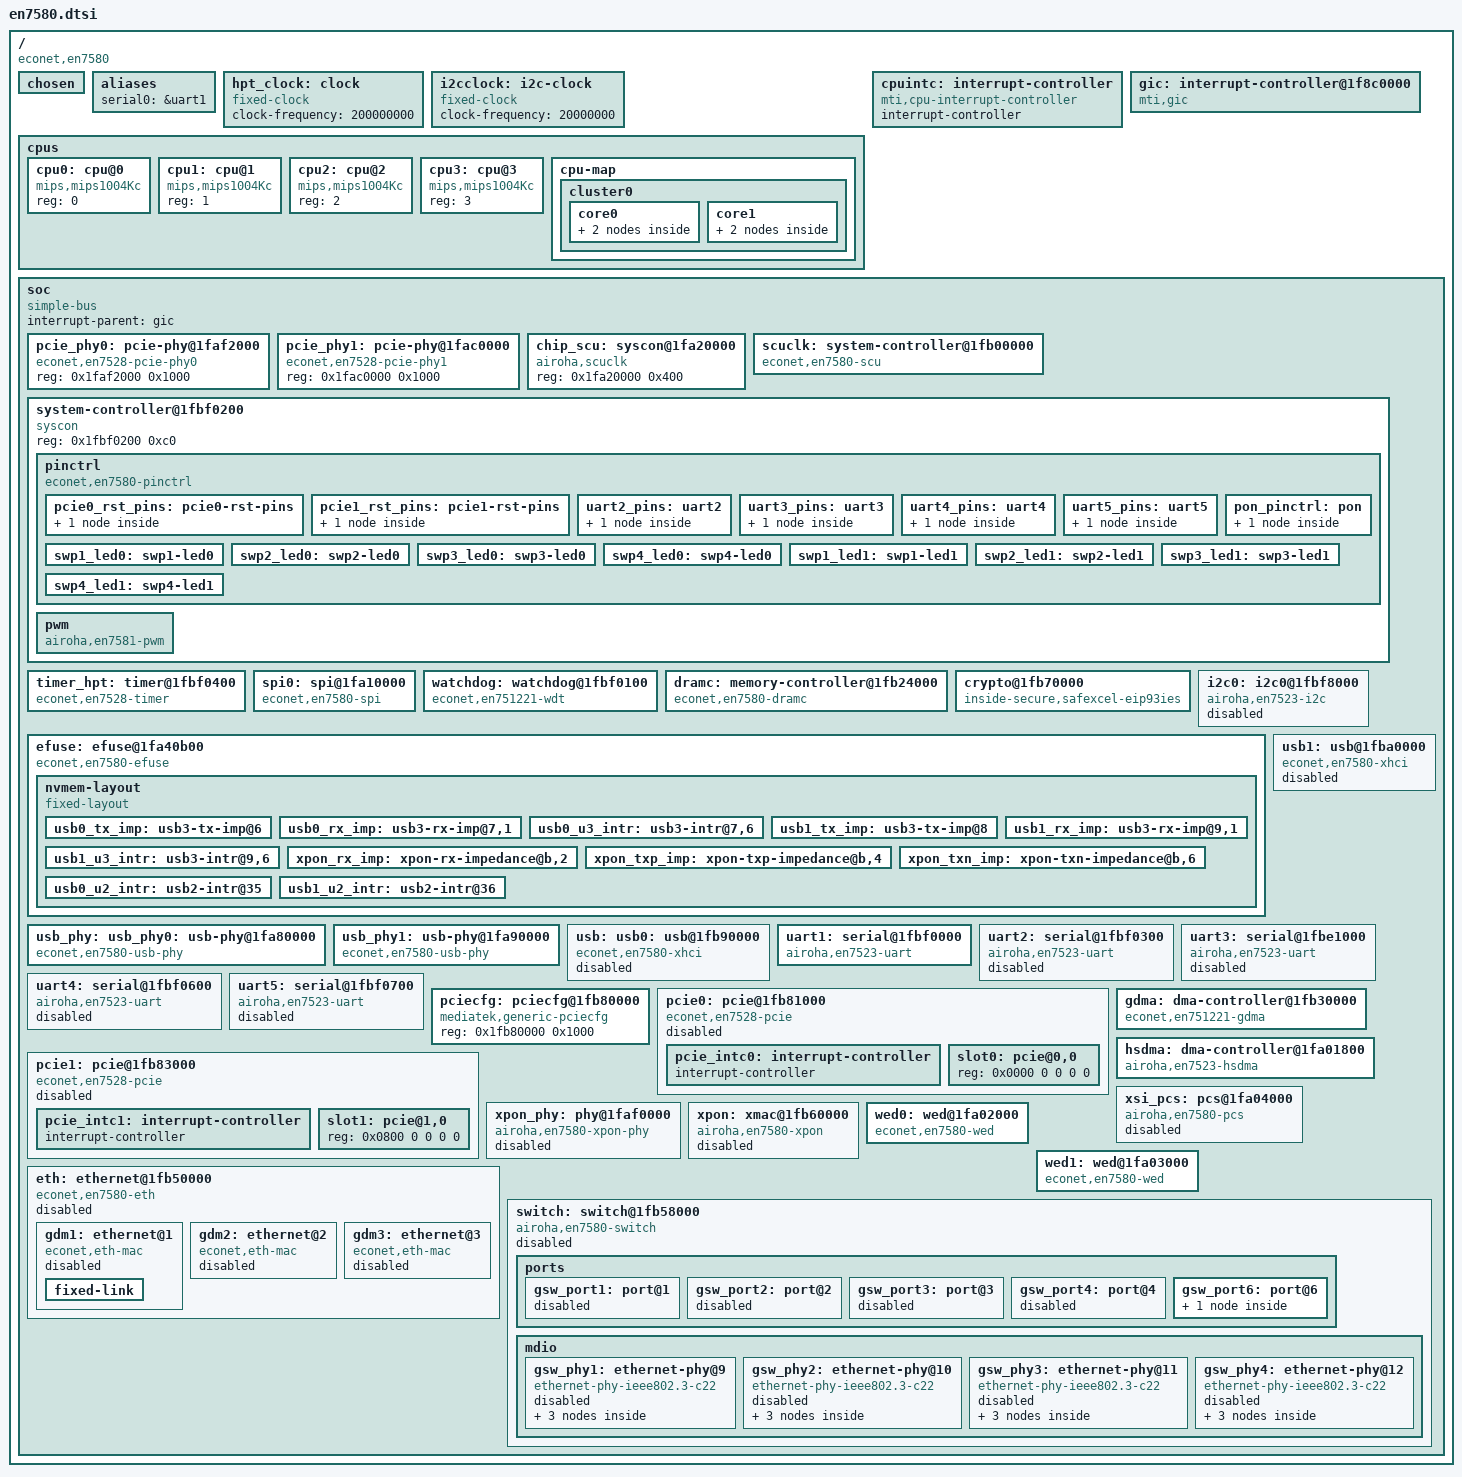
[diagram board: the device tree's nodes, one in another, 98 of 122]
// SPDX-License-Identifier: (GPL-2.0-only OR BSD-2-Clause)
/dts-v1/;

#include <dt-bindings/interrupt-controller/irq.h>
#include <dt-bindings/interrupt-controller/mips-gic.h>
#include <dt-bindings/clock/econet,en7580-scu.h>
#include <dt-bindings/phy/phy.h>
#include <dt-bindings/reset/econet,en7580-scu.h>
#include <dt-bindings/leds/common.h>
#include <dt-bindings/soc/airoha,scu-ssr.h>
#include <dt-bindings/soc/airoha,soc-variant.h>
#include <dt-bindings/gpio/gpio.h>
#include <dt-bindings/input/input.h>

/ {
	compatible = "econet,en7580";
	#address-cells = <1>;
	#size-cells = <1>;

	chosen {
		stdout-path = "serial0:115200n8";
		linux,usable-memory-range = <0x00020000 0x1fe00000>;
	};

	aliases {
		serial0 = &uart1;
	};

	hpt_clock: clock {
		compatible = "fixed-clock";
		#clock-cells = <0>;
		clock-frequency = <200000000>;  /* 200 MHz */
	};

	i2cclock: i2c-clock {
		#clock-cells = <0>;
		compatible = "fixed-clock";

		/* 20 MHz */
		clock-frequency = <20000000>;
	};

	cpus {
		#address-cells = <1>;
		#size-cells = <0>;

		cpu0: cpu@0 {
			device_type = "cpu";
			compatible = "mips,mips1004Kc";
			reg = <0>;
		};

		cpu1: cpu@1 {
			device_type = "cpu";
			compatible = "mips,mips1004Kc";
			reg = <1>;
		};

		cpu2: cpu@2 {
			device_type = "cpu";
			compatible = "mips,mips1004Kc";
			reg = <2>;
		};

		cpu3: cpu@3 {
			device_type = "cpu";
			compatible = "mips,mips1004Kc";
			reg = <3>;
		};

		cpu-map {
			cluster0 {
				core0 {
					thread0 {
						cpu = <&cpu0>;
					};

				thread1 {
					cpu = <&cpu1>;
				};
			};

			core1 {
				thread0 {
					cpu = <&cpu2>;
				};

				thread1 {
						cpu = <&cpu3>;
					};
				};
			};
		};
	};

	cpuintc: interrupt-controller {
		compatible = "mti,cpu-interrupt-controller";
		interrupt-controller;
		#address-cells = <0>;
		#interrupt-cells = <1>;
	};

	gic: interrupt-controller@1f8c0000 {
		compatible = "mti,gic";
		reg = <0x1f8c0000 0x20000>;

		interrupt-controller;
		#interrupt-cells = <3>;

		interrupt-parent = <&cpuintc>;
		interrupts = <2>;
	};

	soc {
		compatible = "simple-bus";
		#address-cells = <1>;
		#size-cells = <1>;
		interrupt-parent = <&gic>;
		ranges;

		pcie_phy0: pcie-phy@1faf2000 {
			compatible = "econet,en7528-pcie-phy0";
			reg = <0x1faf2000 0x1000>;
			#phy-cells = <0>;
		};

		pcie_phy1: pcie-phy@1fac0000 {
			compatible = "econet,en7528-pcie-phy1";
			reg = <0x1fac0000 0x1000>;
			#phy-cells = <0>;
		};

		chip_scu: syscon@1fa20000 {
			compatible = "airoha,scuclk", "econet,en7580-chip-scu", "syscon";
			reg = <0x1fa20000 0x400>;
		};

		scuclk: system-controller@1fb00000 {
			compatible = "econet,en7580-scu", "syscon";
			reg = <0x1fb00000 0x1000>;

			airoha,chip-scu = <&chip_scu>;
			#clock-cells = <1>;
			#reset-cells = <1>;
		};

		system-controller@1fbf0200 {
			compatible = "syscon", "simple-mfd";
			reg = <0x1fbf0200 0xc0>;

			pinctrl: pinctrl {
				compatible = "econet,en7580-pinctrl";
				airoha,chip-scu = <&chip_scu>;

				interrupt-parent = <&gic>;
				interrupts = <GIC_SHARED 10 IRQ_TYPE_LEVEL_HIGH>;

				gpio-controller;
				#gpio-cells = <2>;

				interrupt-controller;
				#interrupt-cells = <2>;

				gpio-ranges = <&pinctrl 0 0 46>;

				pcie0_rst_pins: pcie0-rst-pins {
					conf {
						pins = "pcie_reset0";
						drive-open-drain = <1>;
					};
				};

				pcie1_rst_pins: pcie1-rst-pins {
					conf {
						pins = "pcie_reset1";
						drive-open-drain = <1>;
					};
				};

				uart2_pins: uart2 {
					mux {
						function = "uart";
						groups = "uart2";
					};
				};

				uart3_pins: uart3 {
					mux {
						function = "uart";
						groups = "uart3";
					};
				};

				uart4_pins: uart4 {
					mux {
						function = "uart";
						groups = "uart4";
					};
				};

				uart5_pins: uart5 {
					mux {
						function = "uart";
						groups = "uart5";
					};
				};

				pon_pinctrl: pon {
					mux {
						function = "pon";
						groups = "pon";
					};
				};

				swp1_led0: swp1-led0 {
					function = "phy1_led0";
					groups = "gpio8";
				};

				swp2_led0: swp2-led0 {
					function = "phy2_led0";
					groups = "gpio9";
				};

				swp3_led0: swp3-led0 {
					function = "phy3_led0";
					groups = "gpio10";
				};

				swp4_led0: swp4-led0 {
					function = "phy4_led0";
					groups = "gpio11";
				};

				swp1_led1: swp1-led1 {
					function = "phy1_led1";
					groups = "gpio12";
				};

				swp2_led1: swp2-led1 {
					function = "phy2_led1";
					groups = "gpio13";
				};

				swp3_led1: swp3-led1 {
					function = "phy3_led1";
					groups = "gpio14";
				};

				swp4_led1: swp4-led1 {
					function = "phy4_led1";
					groups = "gpio15";
				};
			};

			pwm: pwm {
				compatible = "airoha,en7581-pwm";

				#pwm-cells = <3>;
			};
		};

		timer_hpt: timer@1fbf0400 {
			compatible = "econet,en7528-timer";
			reg = <0x1fbf0400 0x14>,
			      <0x1fbe0000 0x14>;

			interrupts = <GIC_SHARED 30 IRQ_TYPE_LEVEL_HIGH>,
				     <GIC_SHARED 29 IRQ_TYPE_LEVEL_HIGH>,
				     <GIC_SHARED 37 IRQ_TYPE_LEVEL_HIGH>,
				     <GIC_SHARED 36 IRQ_TYPE_LEVEL_HIGH>;

			clocks = <&hpt_clock>;
		};

		spi0: spi@1fa10000 {
			compatible = "econet,en7580-spi";
			reg = <0x1fa10000 0x140>,
			      <0x1fa11000 0x160>;
			reg-names = "ctrl", "nfi";

			clocks = <&scuclk EN7580_CLK_SPI>;
			clock-names = "spi";

			airoha,scu = <&scuclk>;

			#address-cells = <1>;
			#size-cells = <0>;
		};

		watchdog: watchdog@1fbf0100 {
			compatible = "econet,en751221-wdt";
			reg = <0x1fbf0100 0x3c>;

			clocks = <&scuclk EN7580_CLK_BUS>;
			clock-names = "bus";

			interrupts = <GIC_SHARED 9 IRQ_TYPE_LEVEL_HIGH>;
		};

		dramc: memory-controller@1fb24000 {
			compatible = "econet,en7580-dramc";
			reg = <0x1fb24000 0x1000>,
			      <0x1fb28000 0x1000>;
			reg-names = "dramc", "ddrphy";
			airoha,chip-scu = <&chip_scu>;
		};

		crypto@1fb70000 {
			compatible = "inside-secure,safexcel-eip93ies";
			reg = <0x1fb70000 0x1000>;
			interrupts = <GIC_SHARED 28 IRQ_TYPE_LEVEL_HIGH>;
		};

		i2c0: i2c0@1fbf8000 {
			compatible = "airoha,en7523-i2c";
			reg = <0x1fbf8000 0x100>;

			clocks = <&i2cclock>;

			/* 100 kHz */
			clock-frequency = <100000>;
			#address-cells = <1>;
			#size-cells = <0>;

			status = "disabled";
		};

		efuse: efuse@1fa40b00 {
			compatible = "econet,en7580-efuse";
			reg = <0x1fa40b00 0x3c>;
			read-only;

			nvmem-layout {
				compatible = "fixed-layout";
				#address-cells = <1>;
				#size-cells = <1>;

				usb0_tx_imp: usb3-tx-imp@6 {
					reg = <0x6 0x2>;
					bits = <4 5>;
				};

				usb0_rx_imp: usb3-rx-imp@7,1 {
					reg = <0x7 0x1>;
					bits = <1 5>;
				};

				usb0_u3_intr: usb3-intr@7,6 {
					reg = <0x7 0x2>;
					bits = <6 6>;
				};

				usb1_tx_imp: usb3-tx-imp@8 {
					reg = <0x8 0x2>;
					bits = <4 5>;
				};

				usb1_rx_imp: usb3-rx-imp@9,1 {
					reg = <0x9 0x1>;
					bits = <1 5>;
				};

				usb1_u3_intr: usb3-intr@9,6 {
					reg = <0x9 0x2>;
					bits = <6 6>;
				};

				xpon_rx_imp: xpon-rx-impedance@b,2 {
					reg = <0xb 0x1>;
					bits = <2 2>;
				};

				xpon_txp_imp: xpon-txp-impedance@b,4 {
					reg = <0xb 0x1>;
					bits = <4 2>;
				};

				xpon_txn_imp: xpon-txn-impedance@b,6 {
					reg = <0xb 0x1>;
					bits = <6 2>;
				};

				usb0_u2_intr: usb2-intr@35 {
					reg = <0x35 0x2>;
					bits = <7 5>;
				};

				usb1_u2_intr: usb2-intr@36 {
					reg = <0x36 0x2>;
					bits = <4 5>;
				};
			};
		};

		usb_phy: usb_phy0: usb-phy@1fa80000 {
			compatible = "econet,en7580-usb-phy";
			reg = <0x1fa80000 0x1000>;
			#phy-cells = <1>;
			nvmem-cells = <&usb0_u2_intr>, <&usb0_u3_intr>,
				      <&usb0_tx_imp>, <&usb0_rx_imp>;
			nvmem-cell-names = "u2-intr", "u3-intr", "tx-imp", "rx-imp";
		};

		usb_phy1: usb-phy@1fa90000 {
			compatible = "econet,en7580-usb-phy";
			reg = <0x1fa90000 0x1000>;
			#phy-cells = <1>;
			nvmem-cells = <&usb1_u2_intr>, <&usb1_u3_intr>,
				      <&usb1_tx_imp>, <&usb1_rx_imp>;
			nvmem-cell-names = "u2-intr", "u3-intr", "tx-imp", "rx-imp";
		};

		usb: usb0: usb@1fb90000 {
			compatible = "econet,en7580-xhci";
			reg = <0x1fb90000 0x4000>,
			      <0x1fa84700 0x100>;
			reg-names = "mac", "ippc";
			interrupts = <GIC_SHARED 17 IRQ_TYPE_LEVEL_HIGH>;
			interrupt-names = "host";
			phys = <&usb_phy PHY_TYPE_USB2>, <&usb_phy PHY_TYPE_USB3>;
			phy-names = "usb2-phy", "usb3-phy";
			usb3-lpm-capable;
			status = "disabled";
		};

		usb1: usb@1fba0000 {
			compatible = "econet,en7580-xhci";
			reg = <0x1fba0000 0x4000>,
			      <0x1fa94700 0x100>;
			reg-names = "mac", "ippc";
			interrupts = <GIC_SHARED 48 IRQ_TYPE_LEVEL_HIGH>;
			interrupt-names = "host";
			phys = <&usb_phy1 PHY_TYPE_USB2>, <&usb_phy1 PHY_TYPE_USB3>;
			phy-names = "usb2-phy", "usb3-phy";
			usb3-lpm-capable;
			status = "disabled";
		};

		uart1: serial@1fbf0000 {
			compatible = "airoha,en7523-uart";
			reg = <0x1fbf0000 0x30>;
			reg-io-width = <4>;
			reg-shift = <2>;

			interrupts = <GIC_SHARED 2 IRQ_TYPE_LEVEL_HIGH>;

			/*
			 * The EcoNet/Airoha UART uses the vendor XYD fractional divider.
			 * The generic 8250 driver does not program XYD, so keep the bootloader
			 * XYD setup and expose a fixed 115200 baud base clock.
			 */
			clock-frequency = <1843200>;
		};

		uart2: serial@1fbf0300 {
			compatible = "airoha,en7523-uart";
			reg = <0x1fbf0300 0x30>;
			reg-io-width = <4>;
			reg-shift = <2>;

			interrupts = <GIC_SHARED 16 IRQ_TYPE_LEVEL_HIGH>;

			/*
			 * Keep the XYD configuration programmed by the bootloader.
			 * 1.8432 MHz gives the standard 115200 baud 8250 divisor.
			 */
			clock-frequency = <1843200>;

			pinctrl-names = "default";
			pinctrl-0 = <&uart2_pins>;

			status = "disabled";
		};

		uart3: serial@1fbe1000 {
			compatible = "airoha,en7523-uart";
			reg = <0x1fbe1000 0x30>;
			reg-io-width = <4>;
			reg-shift = <2>;

			interrupts = <GIC_SHARED 38 IRQ_TYPE_LEVEL_HIGH>;

			/*
			 * Keep the XYD configuration programmed by the bootloader.
			 */
			clock-frequency = <1843200>;

			pinctrl-names = "default";
			pinctrl-0 = <&uart3_pins>;

			status = "disabled";
		};

		uart4: serial@1fbf0600 {
			compatible = "airoha,en7523-uart";
			reg = <0x1fbf0600 0x30>;
			reg-io-width = <4>;
			reg-shift = <2>;

			interrupts = <GIC_SHARED 45 IRQ_TYPE_LEVEL_HIGH>;

			/*
			 * Keep the XYD configuration programmed by the bootloader.
			 */
			clock-frequency = <1843200>;

			pinctrl-names = "default";
			pinctrl-0 = <&uart4_pins>;

			status = "disabled";
		};

		uart5: serial@1fbf0700 {
			compatible = "airoha,en7523-uart";
			reg = <0x1fbf0700 0x30>;
			reg-io-width = <4>;
			reg-shift = <2>;

			interrupts = <GIC_SHARED 46 IRQ_TYPE_LEVEL_HIGH>;

			/*
			 * Keep the XYD configuration programmed by the bootloader.
			 */
			clock-frequency = <1843200>;

			pinctrl-names = "default";
			pinctrl-0 = <&uart5_pins>;

			status = "disabled";
		};

		pciecfg: pciecfg@1fb80000 {
			compatible = "mediatek,generic-pciecfg", "syscon";
			reg = <0x1fb80000 0x1000>;
		};

		pcie0: pcie@1fb81000 {
			compatible = "econet,en7528-pcie";
			device_type = "pci";
			reg = <0x1fb81000 0x1000>;
			reg-names = "port0";
			linux,pci-domain = <0>;
			#address-cells = <3>;
			#size-cells = <2>;
			interrupts = <GIC_SHARED 23 IRQ_TYPE_LEVEL_HIGH>;
			interrupt-names = "pcie_irq";
			clocks = <&scuclk EN7580_CLK_PCIE>;
			clock-names = "sys_ck0";
			phys = <&pcie_phy0>;
			phy-names = "pcie-phy0";
			bus-range = <0x00 0xff>;
			ranges = <0x01000000 0 0x00000000 0x1f600000 0 0x00010000>,
				 <0x82000000 0 0x20000000 0x20000000 0 0x08000000>;
			status = "disabled";

			#interrupt-cells = <1>;
			interrupt-map-mask = <0 0 0 7>;
			interrupt-map = <0 0 0 1 &pcie_intc0 0>,
					<0 0 0 2 &pcie_intc0 1>,
					<0 0 0 3 &pcie_intc0 2>,
					<0 0 0 4 &pcie_intc0 3>;

			pcie_intc0: interrupt-controller {
				interrupt-controller;
				#address-cells = <0>;
				#interrupt-cells = <1>;
			};

			slot0: pcie@0,0 {
				reg = <0x0000 0 0 0 0>;
				#address-cells = <3>;
				#size-cells = <2>;
				ranges;
			};
		};

		pcie1: pcie@1fb83000 {
			compatible = "econet,en7528-pcie";
			device_type = "pci";
			reg = <0x1fb83000 0x1000>;
			reg-names = "port1";
			linux,pci-domain = <1>;
			#address-cells = <3>;
			#size-cells = <2>;
			interrupts = <GIC_SHARED 24 IRQ_TYPE_LEVEL_HIGH>;
			interrupt-names = "pcie_irq";
			clocks = <&scuclk EN7580_CLK_PCIE>;
			clock-names = "sys_ck1";
			phys = <&pcie_phy1>;
			phy-names = "pcie-phy1";
			bus-range = <0x00 0xff>;
			ranges = <0x01000000 0 0x00000000 0x1f610000 0 0x00010000>,
				 <0x82000000 0 0x28000000 0x28000000 0 0x08000000>;
			status = "disabled";

			#interrupt-cells = <1>;
			interrupt-map-mask = <0 0 0 7>;
			interrupt-map = <0 0 0 1 &pcie_intc1 0>,
					<0 0 0 2 &pcie_intc1 1>,
					<0 0 0 3 &pcie_intc1 2>,
					<0 0 0 4 &pcie_intc1 3>;

			pcie_intc1: interrupt-controller {
				interrupt-controller;
				#address-cells = <0>;
				#interrupt-cells = <1>;
			};

			slot1: pcie@1,0 {
				reg = <0x0800 0 0 0 0>;
				#address-cells = <3>;
				#size-cells = <2>;
				ranges;
			};
		};

		gdma: dma-controller@1fb30000 {
			compatible = "econet,en751221-gdma";
			reg = <0x1fb30000 0x1000>;

			resets = <&scuclk EN7580_GDMA_RST>;
			interrupts = <GIC_SHARED 14 IRQ_TYPE_LEVEL_HIGH>;

			#dma-cells = <1>;
			dma-channels = <8>;
		};

		hsdma: dma-controller@1fa01800 {
			compatible = "airoha,en7523-hsdma";
			reg = <0x1fa01800 0x300>;

			interrupts = <GIC_SHARED 47 IRQ_TYPE_LEVEL_HIGH>;

			#dma-cells = <1>;
			dma-channels = <2>;
		};

		xsi_pcs: pcs@1fa04000 {
			compatible = "airoha,en7580-pcs";
			reg = <0x1fa04000 0x200>,
			      <0x1faf6000 0x1000>,
			      <0x1faf7900 0x1000>;
			reg-names = "mac", "pma", "pcs";
			airoha,scu = <&scuclk>;
			airoha,chip-scu = <&chip_scu>;
			#pcs-cells = <0>;
			status = "disabled";
		};

		xpon_phy: phy@1faf0000 {
			compatible = "airoha,en7580-xpon-phy";
			reg = <0x1faf0000 0x1000>,
			      <0x1faf3000 0x1000>;
			reg-names = "pcs", "pma";

			nvmem-cells = <&xpon_rx_imp>, <&xpon_txp_imp>, <&xpon_txn_imp>;
			nvmem-cell-names = "rx-impedance", "txp-impedance", "txn-impedance";

			pinctrl-names = "default";
			pinctrl-0 = <&pon_pinctrl>;

			tx-disable-gpios = <&pinctrl 38 GPIO_ACTIVE_HIGH>;

			resets = <&scuclk EN7580_XPON_PHY_RST>;
			reset-names = "phy";

			interrupts = <GIC_SHARED 27 IRQ_TYPE_LEVEL_HIGH>;
			interrupt-names = "phy";

			airoha,scu = <&scuclk>;

			#phy-cells = <0>;
			status = "disabled";
		};

		xpon: xmac@1fb60000 {
			compatible = "airoha,en7580-xpon";

			reg = <0x1fb60000 0x10000>;
			reg-names = "mac";

			interrupts = <GIC_SHARED 26 IRQ_TYPE_LEVEL_HIGH>,
			             <GIC_SHARED 18 IRQ_TYPE_LEVEL_HIGH>;
			interrupt-names = "mac", "dying-gasp";

			resets = <&scuclk EN7580_XPON_MAC_RST>;
			reset-names = "mac";

			phys = <&xpon_phy>;
			phy-names = "xpon";

			ethernet = <&gdm2>;

			airoha,scu = <&scuclk>;

			status = "disabled";
		};

		/* <GIC_SHARED 51 IRQ_TYPE_LEVEL_HIGH> => WIFI Offload Engine 0 */
		/* <GIC_SHARED 53 IRQ_TYPE_LEVEL_HIGH> => WIFI DMA 0 port 0 */
		/* <GIC_SHARED 54 IRQ_TYPE_LEVEL_HIGH> => WIFI DMA 0 port 1 */
		/* <GIC_SHARED 55 IRQ_TYPE_LEVEL_HIGH> => WIFI DMA 0 for WOE */
		wed0: wed@1fa02000 {
			compatible = "econet,en7580-wed", "syscon";
			reg = <0x1fa02000 0xb00>,
			      <0x1fa06000 0x400>;
			reg-names = "wed", "wdma";
			interrupts = <GIC_SHARED 51 IRQ_TYPE_LEVEL_HIGH>;
			airoha,scu = <&scuclk>;
		};

		/* <GIC_SHARED 52 IRQ_TYPE_LEVEL_HIGH> => WIFI Offload Engine 1 */
		/* <GIC_SHARED 56 IRQ_TYPE_LEVEL_HIGH> => WIFI DMA 1 port 0 */
		/* <GIC_SHARED 56 IRQ_TYPE_LEVEL_HIGH> => WIFI DMA 1 port 1 */
		/* <GIC_SHARED 58 IRQ_TYPE_LEVEL_HIGH> => WIFI DMA 1 for WOE */
		wed1: wed@1fa03000 {
			compatible = "econet,en7580-wed", "syscon";
			reg = <0x1fa03000 0xb00>,
			      <0x1fa06400 0x400>;
			reg-names = "wed", "wdma";
			interrupts = <GIC_SHARED 52 IRQ_TYPE_LEVEL_HIGH>;
			airoha,scu = <&scuclk>;
		};

		eth: ethernet@1fb50000 {
			compatible = "econet,en7580-eth";
			status = "disabled";
			reg = <0x1fb50000 0x2600>,
			      <0x1fb54000 0x2000>,
			      <0x1fb56000 0x2000>,
			      <0x1fbf9000 0x1000>;
			reg-names = "fe", "qdma0", "qdma1", "gdmp";

			resets = <&scuclk EN7580_FE_RST>,
				 <&scuclk EN7580_FE_QDMA1_RST>,
				 <&scuclk EN7580_FE_QDMA2_RST>,
				 <&scuclk EN7580_GDMP_RST>;
			reset-names = "fe", "pdma", "qdma", "gdmp";

			interrupts = <GIC_SHARED 21 IRQ_TYPE_LEVEL_HIGH>, /* QDMA LAN0 */
			             <GIC_SHARED 22 IRQ_TYPE_LEVEL_HIGH>, /* QDMA WAN0 */
			             <GIC_SHARED 39 IRQ_TYPE_LEVEL_HIGH>, /* QDMA LAN1 */
			             <GIC_SHARED 40 IRQ_TYPE_LEVEL_HIGH>, /* QDMA LAN2 */
			             <GIC_SHARED 41 IRQ_TYPE_LEVEL_HIGH>, /* QDMA LAN3 */
			             <GIC_SHARED 42 IRQ_TYPE_LEVEL_HIGH>, /* QDMA WAN1 */
			             <GIC_SHARED 43 IRQ_TYPE_LEVEL_HIGH>, /* QDMA WAN2 */
			             <GIC_SHARED 44 IRQ_TYPE_LEVEL_HIGH>, /* QDMA WAN3 */
			             <GIC_SHARED 33 IRQ_TYPE_LEVEL_HIGH>; /* Frame Error */
			interrupt-names = "lan0", "wan0",
			                  "lan1", "lan2", "lan3",
			                  "wan1", "wan2", "wan3", "fe-error";

			#address-cells = <1>;
			#size-cells = <0>;

			gdm1: ethernet@1 {
				compatible = "econet,eth-mac";
				reg = <1>;
				phy-mode = "internal";
				status = "disabled";

				fixed-link {
					speed = <1000>;
					full-duplex;
					pause;
				};
			};

			gdm2: ethernet@2 {
				compatible = "econet,eth-mac";
				reg = <2>;
				phy-mode = "internal";

				status = "disabled";
			};

			gdm3: ethernet@3 {
				compatible = "econet,eth-mac";
				reg = <3>;

				pcs-handle = <&xsi_pcs>;

				status = "disabled";
			};
		};

		switch: switch@1fb58000 {
			compatible = "airoha,en7580-switch", "econet,en7580-switch";
			reg = <0x1fb58000 0x8000>;
			resets = <&scuclk EN7580_GSW_RST>;

			interrupt-controller;
			#interrupt-cells = <1>;
			interrupts = <GIC_SHARED 15 IRQ_TYPE_LEVEL_HIGH>;

			status = "disabled";

			#address-cells = <1>;
			#size-cells = <1>;

			ports {
				#address-cells = <1>;
				#size-cells = <0>;

				gsw_port1: port@1 {
					reg = <1>;
					phy-mode = "internal";
					phy-handle = <&gsw_phy1>;
					status = "disabled";
				};

				gsw_port2: port@2 {
					reg = <2>;
					phy-mode = "internal";
					phy-handle = <&gsw_phy2>;
					status = "disabled";
				};

				gsw_port3: port@3 {
					reg = <3>;
					phy-mode = "internal";
					phy-handle = <&gsw_phy3>;
					status = "disabled";
				};

				gsw_port4: port@4 {
					reg = <4>;
					phy-mode = "internal";
					phy-handle = <&gsw_phy4>;
					status = "disabled";
				};

				gsw_port6: port@6 {
					reg = <6>;
					ethernet = <&gdm1>;
					phy-mode = "internal";

					fixed-link {
						speed = <1000>;
						full-duplex;
						pause;
					};
				};
			};

			mdio: mdio {
				#address-cells = <1>;
				#size-cells = <0>;

				gsw_phy1: ethernet-phy@9 {
					compatible = "ethernet-phy-ieee802.3-c22";
					reg = <9>;
					phy-mode = "internal";
					status = "disabled";

					pinctrl-names = "gbe-led";
					pinctrl-0 = <&swp1_led0 &swp1_led1>;
					airoha,scu = <&scuclk>;

					leds {
						#address-cells = <1>;
						#size-cells = <0>;

						gsw_phy1_led0: led0@0 {
							reg = <0>;
							function = LED_FUNCTION_LAN;
							status = "disabled";
							active-low;
						};

						gsw_phy1_led1: led1@1 {
							reg = <1>;
							status = "disabled";
							function = LED_FUNCTION_ACTIVITY;
							active-low;
						};
					};
				};

				gsw_phy2: ethernet-phy@10 {
					compatible = "ethernet-phy-ieee802.3-c22";
					reg = <10>;
					phy-mode = "internal";
					status = "disabled";

					pinctrl-names = "gbe-led";
					pinctrl-0 = <&swp2_led0 &swp2_led1>;
					airoha,scu = <&scuclk>;

					leds {
						#address-cells = <1>;
						#size-cells = <0>;

						gsw_phy2_led0: led0@0 {
							reg = <0>;
							function = LED_FUNCTION_LAN;
							status = "disabled";
							active-low;
						};

						gsw_phy2_led1: led1@1 {
							reg = <1>;
							status = "disabled";
							function = LED_FUNCTION_ACTIVITY;
							active-low;
						};
					};
				};

				gsw_phy3: ethernet-phy@11 {
					compatible = "ethernet-phy-ieee802.3-c22";
					reg = <11>;
					phy-mode = "internal";
					status = "disabled";

					pinctrl-names = "gbe-led";
					pinctrl-0 = <&swp3_led0 &swp3_led1>;
					airoha,scu = <&scuclk>;

					leds {
						#address-cells = <1>;
						#size-cells = <0>;

						gsw_phy3_led0: led0@0 {
							reg = <0>;
							function = LED_FUNCTION_LAN;
							status = "disabled";
							active-low;
						};

						gsw_phy3_led1: led1@1 {
							reg = <1>;
							status = "disabled";
							function = LED_FUNCTION_ACTIVITY;
							active-low;
						};
					};
				};

				gsw_phy4: ethernet-phy@12 {
					compatible = "ethernet-phy-ieee802.3-c22";
					reg = <12>;
					phy-mode = "internal";
					status = "disabled";

					pinctrl-names = "gbe-led";
					pinctrl-0 = <&swp4_led0 &swp4_led1>;
					airoha,scu = <&scuclk>;

					leds {
						#address-cells = <1>;
						#size-cells = <0>;

						gsw_phy4_led0: led0@0 {
							reg = <0>;
							function = LED_FUNCTION_LAN;
							status = "disabled";
							active-low;
						};

						gsw_phy4_led1: led1@1 {
							reg = <1>;
							status = "disabled";
							function = LED_FUNCTION_ACTIVITY;
							active-low;
						};
					};
				};
			};
		};
	};
};
